# L4_PER1_LA register map
Vendor: Texas Instruments
Peripheral module from a debugger description file (folder DM50x).
Registers are 32-bit, read-only, reset 0x0 unless marked. A register's access mark holds for its fields unless they carry their own. Offsets are as the file gives them; lines under a group give offsets from that group; [hi:lo] are bit positions; {n}, {i} and the like mark numbered series; 'fields as' and 'values as' point back to an identical list; <NAME> marks a mode.

## L4_PER1_LA
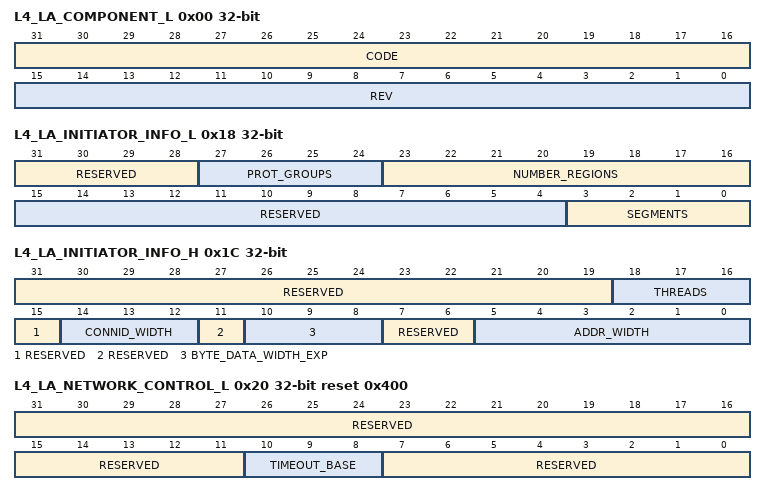
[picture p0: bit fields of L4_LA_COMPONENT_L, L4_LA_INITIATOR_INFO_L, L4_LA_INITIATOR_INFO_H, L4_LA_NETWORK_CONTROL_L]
0x00 L4_LA_COMPONENT_L reset not defined — Contain a component code and revision, which are used to identify the hardware of the component.
  [31:16] CODE — Interconnect code.
  [15:0] REV — Component revision code.
0x04 L4_LA_COMPONENT_H — Contain a component code and revision, which are used to identify the hardware of the component.
  [31:0] RESERVED — Read returns 0.
0x10 L4_LA_NETWORK_L — Identify the interconnect
  [31:0] RESERVED — Read returns 0
0x14 L4_LA_NETWORK_H — Identify the interconnect
  [31:0] ID — The ID field uniquely identifies this interconnect.
0x18 L4_LA_INITIATOR_INFO_L (reset mask 0xF000FFF0) — Contain initiator subsystem information.
  [31:28] RESERVED — Read returns 0.
  [27:24] PROT_GROUPS — Number of protection groups in the current L4 0x0: No protection group 0x1: 1 protection group 0x2: 2 protection groups .... 0x8: 8 protection groups 0x9 to 0xF: Reserved
  [23:16] NUMBER_REGIONS — Number of regions in the current L4 0x0: Reserved 0x1: 1 region 0x2: 2 regions .... Max regions +1 to 0xFF: Reserved, 'Max regions' is listed in on row 'NUMBER_REGIONS'.
  [15:4] RESERVED — Read returns 0.
  [3:0] SEGMENTS — Number of segments in the current L4 0x0: Reserved 0x1: 1 segment 0x2: 2 segments .... 0x8: 8 segments
0x1C L4_LA_INITIATOR_INFO_H (reset mask 0xFFF888C0) — Contain initiator subsystem information.
  [31:19] RESERVED — Read returns 0.
  [18:16] THREADS — The THREADS field specifies the number of initiator threads connected to the interconnect. The field contains read-only configuration information for the initiator subsystem.
  [15] RESERVED — Read returns 0.
  [14:12] CONNID_WIDTH — The initiator subsystem ConnID width. The CONNID_WIDTH field contains read-only configuration information for the initiator subsystem.
  [11] RESERVED — Read returns 0.
  [10:8] BYTE_DATA_WIDTH_EXP — This field specifies the initiator subsystem data width.The BYTE_DATA_WIDTH_EXP field contains read-only configuration information for the initiator subsystem. 0x1: 16-bit data width is specified 0x2: 32-bit data width is specified
  [7:6] RESERVED — Read returns 0.
  [5:0] ADDR_WIDTH — This field specifies the initiator subsystem address width. The ADDR_WIDTH field contains read-only configuration information for the initiator subsystem.
0x20 L4_LA_NETWORK_CONTROL_L access per field reset 0x400 — Control interconnect minimum timeout values.
  [31:11] RESERVED ro — Read returns 0.
  [10:8] TIMEOUT_BASE rw — The TIMEOUT_BASE field indicates the time-out period (that is, base cycles) for the highest frequency time-base signal sent from the L4 initiator subsystem to all target agents that have time-out enabled. Values for the field are: 0 - Time-out disabled 1 - L4 interconnect clock cycles divided by 64 2 - L4 interconnect clock cycles divided by 256 3 - L4 interconnect clock cycles divided by 1024 4 - L4 interconnect clock cycles divided by 4096
  [7:0] RESERVED ro — Read returns 0.
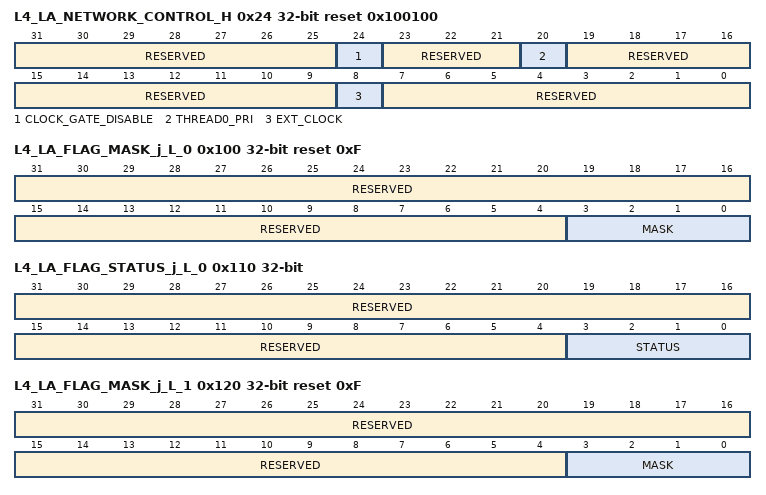
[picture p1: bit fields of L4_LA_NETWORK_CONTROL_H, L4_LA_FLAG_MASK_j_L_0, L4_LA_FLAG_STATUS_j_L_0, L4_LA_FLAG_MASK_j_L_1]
0x24 L4_LA_NETWORK_CONTROL_H access per field reset 0x100100 — Control interconnect global power control
  [31:25] RESERVED ro — Read returns 0.
  [24] CLOCK_GATE_DISABLE rw — When set to 1 this field disables all clock gating.
  [23:21] RESERVED ro — Read returns 0.
  [20] THREAD0_PRI ro — Sets thread priority. If the field is set to 0, the default, all initiator threads are treated the same. Setting the THREAD0_PRI field to 1 assigns a higher arbitration priority to thread 0 of the first initiator OCP interface. To avoid starvation, arbitration is imposed by the initiator subsystem. When multiple requests from different initiator threads are dispatched to targets simultaneously, the oldest request is dispatched first. If thread 0 is assigned a higher priority, a request on thread 0 always wins arbitration. Assigning thread 0 of the first initiator OCP the highest priority on a request or response can result in the starvation of other threads.
  [19:9] RESERVED ro — Read returns 0.
  [8] EXT_CLOCK ro — Global external clock control. When set to 1, the ext_clk_off_i signal on the initiator subsystem instructs the entire L4 to shut off.
  [7:0] RESERVED ro — Read returns 0.
0x100 L4_LA_FLAG_MASK_j_L_0 access per field reset 0xF — Mask of composite sideband flag(0)
  [31:4] RESERVED ro — Read returns 0
  [3:0] MASK rw — Number of input sideband signals
0x104 L4_LA_FLAG_MASK_j_H_0 — Status of composite sideband flag(0)
  [31:0] RESERVED — Read returns 0
0x110 L4_LA_FLAG_STATUS_j_L_0 access per field — Mask of composite sideband flag(1)
  [31:4] RESERVED ro — Read returns 0
  [3:0] STATUS rw — Status of input sideband signals
0x114 L4_LA_FLAG_STATUS_j_H_0 — Status of composite sideband flag(1)
  [31:0] RESERVED — Read returns 0
0x120 L4_LA_FLAG_MASK_j_L_1 access per field reset 0xF — Mask of composite sideband flag(0)
  fields as L4_LA_FLAG_MASK_j_L_0
0x124 L4_LA_FLAG_MASK_j_H_1 — Status of composite sideband flag(0)
  [31:0] RESERVED — Read returns 0
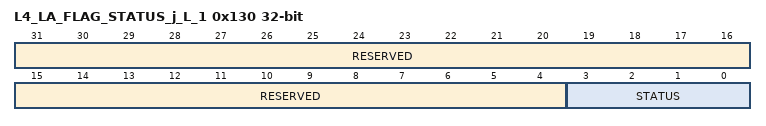
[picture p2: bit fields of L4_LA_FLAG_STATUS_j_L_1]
0x130 L4_LA_FLAG_STATUS_j_L_1 access per field — Mask of composite sideband flag(1)
  fields as L4_LA_FLAG_STATUS_j_L_0
0x134 L4_LA_FLAG_STATUS_j_H_1 — Status of composite sideband flag(1)
  [31:0] RESERVED — Read returns 0
